# MIMXRT1061 register map
Vendor: nxp.com; File version: 1.0
CPU: CM7 r0p1, little endian, MPU, FPU, VTOR, 4 interrupt priority bits
Registers are 32-bit, read-write, reset 0x0 unless marked. A register's access mark holds for its fields unless they carry their own. Offsets are from the block's base; [hi:lo] are bit positions; {n}, {i} and the like mark numbered series; 'fields as' and 'values as' point back to an identical list.

## IOMUXC (part 4 of 4)
Base 0x401F8000; register names take the prefix IOMUXC_
0x4F4 LPSPI1_SDI_SELECT_INPUT — LPSPI1_SDI_SELECT_INPUT DAISY Register
  [0] DAISY — Selecting Pads Involved in Daisy Chain.
    0=GPIO_EMC_29_ALT3 (Selecting Pad: GPIO_EMC_29 for Mode: ALT3); 1=GPIO_SD_B0_03_ALT4 (Selecting Pad: GPIO_AD_B0_03 for Mode: ALT4)
0x4F8 LPSPI1_SDO_SELECT_INPUT — LPSPI1_SDO_SELECT_INPUT DAISY Register
  [0] DAISY — Selecting Pads Involved in Daisy Chain.
    0=GPIO_EMC_28_ALT3 (Selecting Pad: GPIO_EMC_28 for Mode: ALT3); 1=GPIO_SD_B0_02_ALT4 (Selecting Pad: GPIO_SD_B0_02 for Mode: ALT4)
0x4FC LPSPI2_PCS0_SELECT_INPUT — LPSPI2_PCS0_SELECT_INPUT DAISY Register
  [0] DAISY — Selecting Pads Involved in Daisy Chain.
    0=GPIO_SD_B1_06_ALT4 (Selecting Pad: GPIO_SD_B1_06 for Mode: ALT4); 1=GPIO_EMC_01_ALT2 (Selecting Pad: GPIO_EMC_01 for Mode: ALT2)
0x500 LPSPI2_SCK_SELECT_INPUT — LPSPI2_SCK_SELECT_INPUT DAISY Register
  [0] DAISY — Selecting Pads Involved in Daisy Chain.
    0=GPIO_SD_B1_07_ALT4 (Selecting Pad: GPIO_SD_B1_07 for Mode: ALT4); 1=GPIO_EMC_00_ALT2 (Selecting Pad: GPIO_EMC_00 for Mode: ALT2)
0x504 LPSPI2_SDI_SELECT_INPUT — LPSPI2_SDI_SELECT_INPUT DAISY Register
  [0] DAISY — Selecting Pads Involved in Daisy Chain.
    0=GPIO_SD_B1_09_ALT4 (Selecting Pad: GPIO_SD_B1_09 for Mode: ALT4); 1=GPIO_EMC_03_ALT2 (Selecting Pad: GPIO_EMC_03 for Mode: ALT2)
0x508 LPSPI2_SDO_SELECT_INPUT — LPSPI2_SDO_SELECT_INPUT DAISY Register
  [0] DAISY — Selecting Pads Involved in Daisy Chain.
    0=GPIO_SD_B1_08_ALT4 (Selecting Pad: GPIO_SD_B1_08 for Mode: ALT4); 1=GPIO_EMC_02_ALT2 (Selecting Pad: GPIO_EMC_02 for Mode: ALT2)
0x50C LPSPI3_PCS0_SELECT_INPUT — LPSPI3_PCS0_SELECT_INPUT DAISY Register
  [0] DAISY — Selecting Pads Involved in Daisy Chain.
    0=GPIO_AD_B0_03_ALT7 (Selecting Pad: GPIO_AD_B0_03 for Mode: ALT7); 1=GPIO_AD_B1_12_ALT2 (Selecting Pad: GPIO_AD_B1_12 for Mode: ALT2)
0x510 LPSPI3_SCK_SELECT_INPUT — LPSPI3_SCK_SELECT_INPUT DAISY Register
  [0] DAISY — Selecting Pads Involved in Daisy Chain.
    0=GPIO_AD_B0_00_ALT7 (Selecting Pad: GPIO_AD_B0_00 for Mode: ALT7); 1=GPIO_AD_B1_15_ALT2 (Selecting Pad: GPIO_AD_B1_15 for Mode: ALT2)
0x514 LPSPI3_SDI_SELECT_INPUT — LPSPI3_SDI_SELECT_INPUT DAISY Register
  [0] DAISY — Selecting Pads Involved in Daisy Chain.
    0=GPIO_AD_B0_02_ALT7 (Selecting Pad: GPIO_AD_B0_02 for Mode: ALT7); 1=GPIO_AD_B1_13_ALT2 (Selecting Pad: GPIO_AD_B1_13 for Mode: ALT2)
0x518 LPSPI3_SDO_SELECT_INPUT — LPSPI3_SDO_SELECT_INPUT DAISY Register
  [0] DAISY — Selecting Pads Involved in Daisy Chain.
    0=GPIO_AD_B0_01_ALT7 (Selecting Pad: GPIO_AD_B0_01 for Mode: ALT7); 1=GPIO_AD_B1_14_ALT2 (Selecting Pad: GPIO_AD_B1_14 for Mode: ALT2)
0x51C LPSPI4_PCS0_SELECT_INPUT — LPSPI4_PCS0_SELECT_INPUT DAISY Register
  [0] DAISY — Selecting Pads Involved in Daisy Chain.
    0=GPIO_B0_00_ALT3 (Selecting Pad: GPIO_B0_00 for Mode: ALT3); 1=GPIO_B1_04_ALT1 (Selecting Pad:GPIO_B1_04 for Mode: ALT1)
0x520 LPSPI4_SCK_SELECT_INPUT — LPSPI4_SCK_SELECT_INPUT DAISY Register
  [0] DAISY — Selecting Pads Involved in Daisy Chain.
    0=GPIO_B0_03_ALT3 (Selecting Pad: GPIO_B0_03 for Mode: ALT3); 1=GPIO_B1_07_ALT1 (Selecting Pad: GPIO_B1_07 for Mode: ALT1)
0x524 LPSPI4_SDI_SELECT_INPUT — LPSPI4_SDI_SELECT_INPUT DAISY Register
  [0] DAISY — Selecting Pads Involved in Daisy Chain.
    0=GPIO_B0_01_ALT3 (Selecting Pad: GPIO_B0_01 for Mode: ALT3); 1=GPIO_B1_05_ALT1 (Selecting Pad: GPIO_B1_05 for Mode: ALT1)
0x528 LPSPI4_SDO_SELECT_INPUT — LPSPI4_SDO_SELECT_INPUT DAISY Register
  [0] DAISY — Selecting Pads Involved in Daisy Chain.
    0=GPIO_B0_02_ALT3 (Selecting Pad: GPIO_B0_02 for Mode: ALT3); 1=GPIO_B1_06_ALT1 (Selecting Pad: GPIO_B1_06 for Mode: ALT1)
0x52C LPUART2_RX_SELECT_INPUT — LPUART2_RX_SELECT_INPUT DAISY Register
  [0] DAISY — Selecting Pads Involved in Daisy Chain.
    0=GPIO_SD_B1_10_ALT2 (Selecting Pad: GPIO_SD_B1_10 for Mode: ALT2); 1=GPIO_AD_B1_03_ALT2 (Selecting Pad: GPIO_AD_B1_03 for Mode: ALT2)
0x530 LPUART2_TX_SELECT_INPUT — LPUART2_TX_SELECT_INPUT DAISY Register
  [0] DAISY — Selecting Pads Involved in Daisy Chain.
    0=GPIO_SD_B1_11_ALT2 (Selecting Pad: GPIO_SD_B1_11 for Mode: ALT2); 1=GPIO_AD_B1_02_ALT2 (Selecting Pad: GPIO_AD_B1_02 for Mode: ALT2)
0x534 LPUART3_CTS_B_SELECT_INPUT — LPUART3_CTS_B_SELECT_INPUT DAISY Register
  [0] DAISY — Selecting Pads Involved in Daisy Chain.
    0=GPIO_EMC_15_ALT2 (Selecting Pad: GPIO_EMC_15 for Mode: ALT2); 1=GPIO_AD_B1_04_ALT2 (Selecting Pad: GPIO_AD_B1_04 for Mode: ALT2)
0x538 LPUART3_RX_SELECT_INPUT — LPUART3_RX_SELECT_INPUT DAISY Register
  [1:0] DAISY — Selecting Pads Involved in Daisy Chain.
    0=GPIO_AD_B1_07_ALT2 (Selecting Pad: GPIO_AD_B1_07 for Mode: ALT2); 1=GPIO_EMC_14_ALT2 (Selecting Pad: GPIO_EMC_14 for Mode: ALT2); 2=GPIO_B0_09_ALT3 (Selecting Pad: GPIO_B0_09 for Mode: ALT3)
0x53C LPUART3_TX_SELECT_INPUT — LPUART3_TX_SELECT_INPUT DAISY Register
  [1:0] DAISY — Selecting Pads Involved in Daisy Chain.
    0=GPIO_AD_B1_06_ALT2 (Selecting Pad: GPIO_AD_B1_06 for Mode: ALT2); 1=GPIO_EMC_13_ALT2 (Selecting Pad: GPIO_EMC_13 for Mode: ALT2); 2=GPIO_B0_08_ALT3 (Selecting Pad: GPIO_B0_08 for Mode: ALT3)
0x540 LPUART4_RX_SELECT_INPUT — LPUART4_RX_SELECT_INPUT DAISY Register
  [1:0] DAISY — Selecting Pads Involved in Daisy Chain.
    0=GPIO_SD_B1_01_ALT4 (Selecting Pad: GPIO_SD_B1_01 for Mode: ALT4); 1=GPIO_EMC_20_ALT2 (Selecting Pad: GPIO_EMC_20 for Mode: ALT2); 2=GPIO_B1_01_ALT2 (Selecting Pad: GPIO_B1_01 for Mode: ALT2)
0x544 LPUART4_TX_SELECT_INPUT — LPUART4_TX_SELECT_INPUT DAISY Register
  [1:0] DAISY — Selecting Pads Involved in Daisy Chain.
    0=GPIO_SD_B1_00_ALT4 (Selecting Pad: GPIO_SD_B1_00 for Mode: ALT4); 1=GPIO_EMC_19_ALT2 (Selecting Pad: GPIO_EMC_19 for Mode: ALT2); 2=GPIO_B1_00_ALT2 (Selecting Pad: GPIO_B1_00 for Mode: ALT2)
0x548 LPUART5_RX_SELECT_INPUT — LPUART5_RX_SELECT_INPUT DAISY Register
  [0] DAISY — Selecting Pads Involved in Daisy Chain.
    0=GPIO_EMC_24_ALT2 (Selecting Pad: GPIO_EMC_24 for Mode: ALT2); 1=GPIO_B1_13_ALT1 (Selecting Pad: GPIO_B1_13 for Mode: ALT1)
0x54C LPUART5_TX_SELECT_INPUT — LPUART5_TX_SELECT_INPUT DAISY Register
  [0] DAISY — Selecting Pads Involved in Daisy Chain.
    0=GPIO_EMC_23_ALT2 (Selecting Pad: GPIO_EMC_23 for Mode: ALT2); 1=GPIO_B1_12_ALT1 (Selecting Pad: GPIO_B1_12 for Mode: ALT1)
0x550 LPUART6_RX_SELECT_INPUT — LPUART6_RX_SELECT_INPUT DAISY Register
  [0] DAISY — Selecting Pads Involved in Daisy Chain.
    0=GPIO_EMC_26_ALT2 (Selecting Pad: GPIO_EMC_26 for Mode: ALT2); 1=GPIO_AD_B0_03_ALT2 (Selecting Pad: GPIO_AD_B0_03 for Mode: ALT2)
0x554 LPUART6_TX_SELECT_INPUT — LPUART6_TX_SELECT_INPUT DAISY Register
  [0] DAISY — Selecting Pads Involved in Daisy Chain.
    0=GPIO_EMC_25_ALT2 (Selecting Pad: GPIO_EMC_25 for Mode: ALT2); 1=GPIO_AD_B0_02_ALT2 (Selecting Pad: GPIO_AD_B0_02 for Mode: ALT2)
0x558 LPUART7_RX_SELECT_INPUT — LPUART7_RX_SELECT_INPUT DAISY Register
  [0] DAISY — Selecting Pads Involved in Daisy Chain.
    0=GPIO_SD_B1_09_ALT2 (Selecting Pad: GPIO_SD_B1_09 for Mode: ALT2); 1=GPIO_EMC_32_ALT2 (Selecting Pad: GPIO_EMC_32 for Mode: ALT2)
0x55C LPUART7_TX_SELECT_INPUT — LPUART7_TX_SELECT_INPUT DAISY Register
  [0] DAISY — Selecting Pads Involved in Daisy Chain.
    0=GPIO_SD_B1_08_ALT2 (Selecting Pad: GPIO_SD_B1_08 for Mode: ALT2); 1=GPIO_EMC_31_ALT2 (Selecting Pad:GPIO_EMC_31 for Mode: ALT2)
0x560 LPUART8_RX_SELECT_INPUT — LPUART8_RX_SELECT_INPUT DAISY Register
  [1:0] DAISY — Selecting Pads Involved in Daisy Chain.
    0=GPIO_SD_B0_05_ALT2 (Selecting Pad: GPIO_SD_B0_05 for Mode: ALT2); 1=GPIO_AD_B1_11_ALT2 (Selecting Pad: GPIO_AD_B1_11 for Mode: ALT2); 2=GPIO_EMC_39_ALT2 (Selecting Pad: GPIO_EMC_39 for Mode: ALT2)
0x564 LPUART8_TX_SELECT_INPUT — LPUART8_TX_SELECT_INPUT DAISY Register
  [1:0] DAISY — Selecting Pads Involved in Daisy Chain.
    0=GPIO_SD_B0_04_ALT2 (Selecting Pad: GPIO_SD_B0_04 for Mode: ALT2); 1=GPIO_AD_B1_10_ALT2 (Selecting Pad: GPIO_AD_B1_10 for Mode: ALT2); 2=GPIO_EMC_38_ALT2 (Selecting Pad: GPIO_EMC_38 for Mode: ALT2)
0x568 NMI_SELECT_INPUT — NMI_GLUE_NMI_SELECT_INPUT DAISY Register
  [0] DAISY — Selecting Pads Involved in Daisy Chain.
    0=GPIO_AD_B0_12_ALT7 (Selecting Pad: GPIO_AD_B0_12 for Mode: ALT7); 1=WAKEUP_ALT7 (Selecting Pad: WAKEUP for Mode: ALT7)
{0x56C+4i} QTIMER2_TIMER{i}_SELECT_INPUT (i=0..2) — QTIMER2_TIMER{i}_SELECT_INPUT DAISY Register
  [0] DAISY — Selecting Pads Involved in Daisy Chain.
    0=GPIO_EMC_{i+19}_ALT4 (Selecting Pad: GPIO_EMC_{i+19} for Mode: ALT4); 1=GPIO_B0_{i+3:02}_ALT1 (Selecting Pad: GPIO_B0_{i+3:02} for Mode: ALT1)
0x578 QTIMER2_TIMER3_SELECT_INPUT — QTIMER2_TIMER3_SELECT_INPUT DAISY Register
  [0] DAISY — Selecting Pads Involved in Daisy Chain.
    0=GPIO_EMC_22_ALT4 (Selecting Pad: GPIO_EMC_22 for Mode: ALT4); 1=GPIO_B1_09_ALT1 (Selecting Pad: GPIO_B1_09 for Mode: ALT1)
0x57C QTIMER3_TIMER0_SELECT_INPUT — QTIMER3_TIMER0_SELECT_INPUT DAISY Register
  [1:0] DAISY — Selecting Pads Involved in Daisy Chain.
    0=GPIO_EMC_15_ALT4 (Selecting Pad: GPIO_EMC_15 for Mode: ALT4); 1=GPIO_AD_B1_00_ALT1 (Selecting Pad: GPIO_AD_B1_00 for Mode: ALT1); 2=GPIO_B0_06_ALT1 (Selecting Pad: GPIO_B0_06 for Mode: ALT1)
0x580 QTIMER3_TIMER1_SELECT_INPUT — QTIMER3_TIMER1_SELECT_INPUT DAISY Register
  [1:0] DAISY — Selecting Pads Involved in Daisy Chain.
    0=GPIO_AD_B1_01_ALT1 (Selecting Pad: GPIO_AD_B1_01 for Mode: ALT1); 1=GPIO_EMC_16_ALT4 (Selecting Pad: GPIO_EMC_16 for Mode: ALT4); 2=GPIO_B0_07_ALT1 (Selecting Pad: GPIO_B0_07 for Mode: ALT1)
0x584 QTIMER3_TIMER2_SELECT_INPUT — QTIMER3_TIMER2_SELECT_INPUT DAISY Register
  [1:0] DAISY — Selecting Pads Involved in Daisy Chain.
    0=GPIO_EMC_17_ALT4 (Selecting Pad: GPIO_EMC_17 for Mode: ALT4); 1=GPIO_AD_B1_02_ALT1 (Selecting Pad: GPIO_AD_B1_02 for Mode: ALT1); 2=GPIO_B0_08_ALT1 (Selecting Pad: GPIO_B0_08 for Mode: ALT1)
0x588 QTIMER3_TIMER3_SELECT_INPUT — QTIMER3_TIMER3_SELECT_INPUT DAISY Register
  [1:0] DAISY — Selecting Pads Involved in Daisy Chain.
    0=GPIO_EMC_18_ALT4 (Selecting Pad: GPIO_EMC_18 for Mode: ALT4); 1=GPIO_AD_B1_03_ALT1 (Selecting Pad: GPIO_AD_B1_03 for Mode: ALT1); 2=GPIO_B1_10_ALT1 (Selecting Pad: GPIO_B1_10 for Mode: ALT1)
0x58C SAI1_MCLK2_SELECT_INPUT — SAI1_MCLK2_SELECT_INPUT DAISY Register
  [1:0] DAISY — Selecting Pads Involved in Daisy Chain.
    0=GPIO_SD_B1_03_ALT3 (Selecting Pad: GPIO_SD_B1_03 for Mode: ALT3); 1=GPIO_AD_B1_09_ALT3 (Selecting Pad: GPIO_AD_B1_09 for Mode: ALT3); 2=GPIO_B0_13_ALT3 (Selecting Pad: GPIO_B0_13 for Mode: ALT3)
0x590 SAI1_RX_BCLK_SELECT_INPUT — SAI1_RX_BCLK_SELECT_INPUT DAISY Register
  [1:0] DAISY — Selecting Pads Involved in Daisy Chain.
    0=GPIO_SD_B1_05_ALT3 (Selecting Pad: GPIO_SD_B1_05 for Mode: ALT3); 1=GPIO_AD_B1_11_ALT3 (Selecting Pad: GPIO_AD_B1_11 for Mode: ALT3); 2=GPIO_B0_15_ALT3 (Selecting Pad: GPIO_B0_15 for Mode: ALT3)
0x594 SAI1_RX_DATA0_SELECT_INPUT — SAI1_RX_DATA0_SELECT_INPUT DAISY Register
  [1:0] DAISY — Selecting Pads Involved in Daisy Chain.
    0=GPIO_SD_B1_06_ALT3 (Selecting Pad: GPIO_SD_B1_06 for Mode: ALT3); 1=GPIO_AD_B1_12_ALT3 (Selecting Pad: GPIO_AD_B1_12 for Mode: ALT3); 2=GPIO_B1_00_ALT3 (Selecting Pad: GPIO_B1_00 for Mode: ALT3)
{0x594+4i} SAI1_RX_DATA{i}_SELECT_INPUT (i=1..3) — SAI1_RX_DATA{i}_SELECT_INPUT DAISY Register
  [0] DAISY — Selecting Pads Involved in Daisy Chain.
    0=GPIO_SD_B1_{i-1:02}_ALT3 (Selecting Pad: GPIO_SD_B1_{i-1:02} for Mode: ALT3); 1=GPIO_B0_{i+9}_ALT3 (Selecting Pad: GPIO_B0_{i+9} for Mode: ALT3)
0x5A4 SAI1_RX_SYNC_SELECT_INPUT — SAI1_RX_SYNC_SELECT_INPUT DAISY Register
  [1:0] DAISY — Selecting Pads Involved in Daisy Chain.
    0=GPIO_SD_B1_04_ALT3 (Selecting Pad: GPIO_SD_B1_04 for Mode: ALT3); 1=GPIO_AD_B1_10_ALT3 (Selecting Pad: GPIO_AD_B1_10 for Mode: ALT3); 2=GPIO_B0_14_ALT3 (Selecting Pad: GPIO_B0_14 for Mode: ALT3)
0x5A8 SAI1_TX_BCLK_SELECT_INPUT — SAI1_TX_BCLK_SELECT_INPUT DAISY Register
  [1:0] DAISY — Selecting Pads Involved in Daisy Chain.
    0=GPIO_SD_B1_08_ALT3 (Selecting Pad: GPIO_SD_B1_08 for Mode: ALT3); 1=GPIO_AD_B1_14_ALT3 (Selecting Pad: GPIO_AD_B1_14 for Mode: ALT3); 2=GPIO_B1_02_ALT3 (Selecting Pad: GPIO_B1_02 for Mode: ALT3)
0x5AC SAI1_TX_SYNC_SELECT_INPUT — SAI1_TX_SYNC_SELECT_INPUT DAISY Register
  [1:0] DAISY — Selecting Pads Involved in Daisy Chain.
    0=GPIO_SD_B1_09_ALT3 (Selecting Pad: GPIO_SD_B1_09 for Mode: ALT3); 1=GPIO_AD_B1_15_ALT3 (Selecting Pad: GPIO_AD_B1_15 for Mode: ALT3); 2=GPIO_B1_03_ALT3 (Selecting Pad: GPIO_B1_03 for Mode: ALT3)
0x5B0 SAI2_MCLK2_SELECT_INPUT — SAI2_MCLK2_SELECT_INPUT DAISY Register
  [0] DAISY — Selecting Pads Involved in Daisy Chain.
    0=GPIO_EMC_07_ALT2 (Selecting Pad: GPIO_EMC_07 for Mode: ALT2); 1=GPIO_AD_B0_10_ALT3 (Selecting Pad: GPIO_AD_B0_10 for Mode: ALT3)
0x5B4 SAI2_RX_BCLK_SELECT_INPUT — SAI2_RX_BCLK_SELECT_INPUT DAISY Register
  [0] DAISY — Selecting Pads Involved in Daisy Chain.
    0=GPIO_EMC_10_ALT2 (Selecting Pad: GPIO_EMC_10 for Mode: ALT2); 1=GPIO_AD_B0_06_ALT3 (Selecting Pad: GPIO_AD_B0_06 for Mode: ALT3)
0x5B8 SAI2_RX_DATA0_SELECT_INPUT — SAI2_RX_DATA0_SELECT_INPUT DAISY Register
  [0] DAISY — Selecting Pads Involved in Daisy Chain.
    0=GPIO_EMC_08_ALT2 (Selecting Pad: GPIO_EMC_08 for Mode: ALT2); 1=GPIO_AD_B0_08_ALT3 (Selecting Pad: GPIO_AD_B0_08 for Mode: ALT3)
0x5BC SAI2_RX_SYNC_SELECT_INPUT — SAI2_RX_SYNC_SELECT_INPUT DAISY Register
  [0] DAISY — Selecting Pads Involved in Daisy Chain.
    0=GPIO_EMC_09_ALT2 (Selecting Pad: GPIO_EMC_09 for Mode: ALT2); 1=GPIO_AD_B0_07_ALT3 (Selecting Pad: GPIO_AD_B0_07 for Mode: ALT3)
0x5C0 SAI2_TX_BCLK_SELECT_INPUT — SAI2_TX_BCLK_SELECT_INPUT DAISY Register
  [0] DAISY — Selecting Pads Involved in Daisy Chain.
    0=GPIO_EMC_06_ALT2 (Selecting Pad: GPIO_EMC_06 for Mode: ALT2); 1=GPIO_AD_B0_05_ALT3 (Selecting Pad: GPIO_AD_B0_05 for Mode: ALT3)
0x5C4 SAI2_TX_SYNC_SELECT_INPUT — SAI2_TX_SYNC_SELECT_INPUT DAISY Register
  [0] DAISY — Selecting Pads Involved in Daisy Chain.
    0=GPIO_EMC_05_ALT2 (Selecting Pad: GPIO_EMC_05 for Mode: ALT2); 1=GPIO_AD_B0_04_ALT3 (Selecting Pad: GPIO_AD_B0_04 for Mode: ALT3)
0x5C8 SPDIF_IN_SELECT_INPUT — SPDIF_IN_SELECT_INPUT DAISY Register
  [0] DAISY — Selecting Pads Involved in Daisy Chain.
    0=GPIO_AD_B1_03_ALT3 (Selecting Pad: GPIO_AD_B1_03 for Mode: ALT3); 1=GPIO_EMC_16_ALT3 (Selecting Pad: GPIO_EMC_16 for Mode: ALT3)
0x5CC USB_OTG2_OC_SELECT_INPUT — USB_OTG2_OC_SELECT_INPUT DAISY Register
  [0] DAISY — Selecting Pads Involved in Daisy Chain.
    0=GPIO_AD_B0_14_ALT0 (Selecting Pad: GPIO_AD_B0_14 for Mode: ALT0); 1=GPIO_EMC_40_ALT3 (Selecting Pad: GPIO_EMC_40 for Mode: ALT3)
0x5D0 USB_OTG1_OC_SELECT_INPUT — USB_OTG1_OC_SELECT_INPUT DAISY Register
  [0] DAISY — Selecting Pads Involved in Daisy Chain.
    0=GPIO_AD_B0_03_ALT3 (Selecting Pad: GPIO_AD_B0_03 for Mode: ALT3); 1=GPIO_AD_B1_03_ALT0 (Selecting Pad: GPIO_AD_B1_03 for Mode: ALT0)
0x5D4 USDHC1_CD_B_SELECT_INPUT — USDHC1_CD_B_SELECT_INPUT DAISY Register
  [1:0] DAISY — Selecting Pads Involved in Daisy Chain.
    0=GPIO_EMC_35_ALT6 (Selecting Pad: GPIO_EMC_35 for Mode: ALT6); 1=GPIO_AD_B1_02_ALT6 (Selecting Pad: GPIO_AD_B1_02 for Mode: ALT6); 2=GPIO_B1_12_ALT6 (Selecting Pad: GPIO_B1_12 for Mode: ALT6)
0x5D8 USDHC1_WP_SELECT_INPUT — USDHC1_WP_SELECT_INPUT DAISY Register
  [1:0] DAISY — Selecting Pads Involved in Daisy Chain.
    0=GPIO_EMC_12_ALT3 (Selecting Pad: GPIO_EMC_12 for Mode: ALT3); 1=GPIO_EMC_36_ALT6 (Selecting Pad: GPIO_EMC_36for Mode: ALT6); 2=GPIO_AD_B1_00_ALT6 (Selecting Pad:GPIO_AD_B1_00 for Mode: ALT6); 3=GPIO_B1_13_ALT6 (Selecting Pad: GPIO_B1_13 for Mode: ALT6)
0x5DC USDHC2_CLK_SELECT_INPUT — USDHC2_CLK_SELECT_INPUT DAISY Register
  [0] DAISY — Selecting Pads Involved in Daisy Chain.
    0=GPIO_SD_B1_04_ALT0 (Selecting Pad: GPIO_SD_B1_04 for Mode: ALT0); 1=GPIO_AD_B1_09_ALT6 (Selecting Pad: GPIO_AD_B1_09 for Mode: ALT6)
0x5E0 USDHC2_CD_B_SELECT_INPUT — USDHC2_CD_B_SELECT_INPUT DAISY Register
  [0] DAISY — Selecting Pads Involved in Daisy Chain.
    0=GPIO_AD_B1_03_ALT6 (Selecting Pad:GPIO_AD_B1_03 for Mode: ALT6); 1=GPIO_EMC_39_ALT6 (Selecting Pad: GPIO_EMC_39 for Mode: ALT6)
0x5E4 USDHC2_CMD_SELECT_INPUT — USDHC2_CMD_SELECT_INPUT DAISY Register
  [0] DAISY — Selecting Pads Involved in Daisy Chain.
    0=GPIO_SD_B1_05_ALT0 (Selecting Pad: GPIO_SD_B1_05 for Mode: ALT0); 1=GPIO_AD_B1_08_ALT6 (Selecting Pad: GPIO_AD_B1_08 for Mode: ALT6)
0x5E8 USDHC2_DATA0_SELECT_INPUT — USDHC2_DATA0_SELECT_INPUT DAISY Register
  [0] DAISY — Selecting Pads Involved in Daisy Chain.
    0=GPIO_SD_B1_03_ALT0 (Selecting Pad: GPIO_SD_B1_03 for Mode: ALT0); 1=GPIO_AD_B1_04_ALT6 (Selecting Pad:GPIO_AD_B1_04 for Mode: ALT6)
0x5EC USDHC2_DATA1_SELECT_INPUT — USDHC2_DATA1_SELECT_INPUT DAISY Register
  [0] DAISY — Selecting Pads Involved in Daisy Chain.
    0=GPIO_SD_B1_02_ALT0 (Selecting Pad: GPIO_SD_B1_02 for Mode: ALT0); 1=GPIO_AD_B1_05_ALT6 (Selecting Pad: GPIO_AD_B1_05 for Mode: ALT6)
0x5F0 USDHC2_DATA2_SELECT_INPUT — USDHC2_DATA2_SELECT_INPUT DAISY Register
  [0] DAISY — Selecting Pads Involved in Daisy Chain.
    0=GPIO_SD_B1_01_ALT0 (Selecting Pad: GPIO_SD_B1_01 for Mode: ALT0); 1=GPIO_AD_B1_06_ALT6 (Selecting Pad: GPIO_AD_B1_06 for Mode: ALT6)
0x5F4 USDHC2_DATA3_SELECT_INPUT — USDHC2_DATA3_SELECT_INPUT DAISY Register
  [0] DAISY — Selecting Pads Involved in Daisy Chain.
    0=GPIO_SD_B1_00_ALT0 (Selecting Pad: GPIO_SD_B1_00 for Mode: ALT0); 1=GPIO_AD_B1_07_ALT6 (Selecting Pad: GPIO_AD_B1_07 for Mode: ALT6)
{0x5E8+4i} USDHC2_DATA{i}_SELECT_INPUT (i=4..7) — USDHC2_DATA{i}_SELECT_INPUT DAISY Register
  [0] DAISY — Selecting Pads Involved in Daisy Chain.
    0=GPIO_SD_B1_{i+4:02}_ALT0 (Selecting Pad: GPIO_SD_B1_{i+4:02} for Mode: ALT0); 1=GPIO_AD_B1_{i+8}_ALT6 (Selecting Pad: GPIO_AD_B1_{i+8} for Mode: ALT6)
0x608 USDHC2_WP_SELECT_INPUT — USDHC2_WP_SELECT_INPUT DAISY Register
  [0] DAISY — Selecting Pads Involved in Daisy Chain.
    0=GPIO_EMC_37_ALT6 (Selecting Pad: GPIO_EMC_37 for Mode: ALT6); 1=GPIO_AD_B1_10_ALT6 (Selecting Pad: GPIO_AD_B1_10 for Mode: ALT6)
0x60C XBAR1_IN02_SELECT_INPUT — XBAR1_IN02_SELECT_INPUT DAISY Register
  [0] DAISY — Selecting Pads Involved in Daisy Chain.
    0=GPIO_EMC_00_ALT3 (Selecting Pad: GPIO_EMC_00 for Mode: ALT3); 1=GPIO_B1_14_ALT3 (Selecting Pad: GPIO_B1_14 for Mode: ALT3)
0x610 XBAR1_IN03_SELECT_INPUT — XBAR1_IN03_SELECT_INPUT DAISY Register
  [0] DAISY — Selecting Pads Involved in Daisy Chain.
    0=GPIO_EMC_01_ALT3 (Selecting Pad: GPIO_EMC_01 for Mode: ALT3); 1=GPIO_B1_15_ALT3 (Selecting Pad: GPIO_B1_15 for Mode: ALT3)
{0x604+4i} XBAR1_IN{i:02}_SELECT_INPUT (i=4..9) — XBAR1_IN{i:02}_SELECT_INPUT DAISY Register
  [0] DAISY — Selecting Pads Involved in Daisy Chain.
    0=GPIO_EMC_{i-2:02}_ALT3 (Selecting Pad: GPIO_EMC_{i-2:02} for Mode: ALT3); 1=GPIO_SD_B0_{i-4:02}_ALT3 (Selecting Pad: GPIO_SD_B0_{i-4:02} for Mode: ALT3)
0x62C XBAR1_IN17_SELECT_INPUT — XBAR1_IN17_SELECT_INPUT DAISY Register
  [1:0] DAISY — Selecting Pads Involved in Daisy Chain.
    0=GPIO_EMC_08_ALT3 (Selecting Pad: GPIO_EMC_08 for Mode: ALT3); 1=GPIO_AD_B0_03_ALT1 (Selecting Pad: GPIO_AD_B0_03 for Mode: ALT1); 2=GPIO_AD_B0_05_ALT6 (Selecting Pad: GPIO_AD_B0_05 for Mode: ALT6); 3=GPIO_B1_03_ALT1 (Selecting Pad: GPIO_B1_03 for Mode: ALT1)
0x630 XBAR1_IN18_SELECT_INPUT — XBAR1_IN18_SELECT_INPUT DAISY Register
  [0] DAISY — Selecting Pads Involved in Daisy Chain.
    0=GPIO_EMC_35_ALT1 (Selecting Pad: GPIO_EMC_35 for Mode: ALT1); 1=GPIO_AD_B0_06_ALT6 (Selecting Pad: GPIO_AD_B0_06 for Mode: ALT6)
0x634 XBAR1_IN20_SELECT_INPUT — XBAR1_IN20_SELECT_INPUT DAISY Register
  [0] DAISY — Selecting Pads Involved in Daisy Chain.
    0=GPIO_EMC_15_ALT1 (Selecting Pad: GPIO_EMC_15 for Mode: ALT1); 1=GPIO_AD_B0_08_ALT6 (Selecting Pad: GPIO_AD_B0_08 for Mode: ALT6)
0x638 XBAR1_IN22_SELECT_INPUT — XBAR1_IN22_SELECT_INPUT DAISY Register
  [0] DAISY — Selecting Pads Involved in Daisy Chain.
    0=GPIO_EMC_36_ALT1 (Selecting Pad: GPIO_EMC_36 for Mode: ALT1); 1=GPIO_AD_B0_10_ALT6 (Selecting Pad: GPIO_AD_B0_10 for Mode: ALT6)
0x63C XBAR1_IN23_SELECT_INPUT — XBAR1_IN23_SELECT_INPUT DAISY Register
  [0] DAISY — Selecting Pads Involved in Daisy Chain.
    0=GPIO_EMC_37_ALT1 (Selecting Pad: GPIO_EMC_37 for Mode: ALT1); 1=GPIO_AD_B0_11_ALT6 (Selecting Pad: GPIO_AD_B0_11 for Mode: ALT6)
0x640 XBAR1_IN24_SELECT_INPUT — XBAR1_IN24_SELECT_INPUT DAISY Register
  [0] DAISY — Selecting Pads Involved in Daisy Chain.
    0=GPIO_EMC_12_ALT1 (Selecting Pad: GPIO_EMC_12 for Mode: ALT1); 1=GPIO_AD_B0_14_ALT1 (Selecting Pad: GPIO_AD_B0_14 for Mode: ALT1)
0x644 XBAR1_IN14_SELECT_INPUT — XBAR1_IN14_SELECT_INPUT DAISY Register
  [0] DAISY — Selecting Pads Involved in Daisy Chain.
    0=GPIO_AD_B0_00_ALT1 (Selecting Pad: GPIO_AD_B0_00 for Mode: ALT1); 1=GPIO_B1_00_ALT1 (Selecting Pad:GPIO_B1_00 for Mode: ALT1)
0x648 XBAR1_IN15_SELECT_INPUT — XBAR1_IN15_SELECT_INPUT DAISY Register
  [0] DAISY — Selecting Pads Involved in Daisy Chain.
    0=GPIO_AD_B0_01_ALT1 (Selecting Pad: GPIO_AD_B0_01 for Mode: ALT1); 1=GPIO_B1_01_ALT1 (Selecting Pad: GPIO_B1_01 for Mode: ALT1)
0x64C XBAR1_IN16_SELECT_INPUT — XBAR1_IN16_SELECT_INPUT DAISY Register
  [0] DAISY — Selecting Pads Involved in Daisy Chain.
    0=GPIO_AD_B0_02_ALT1 (Selecting Pad: GPIO_AD_B0_02 for Mode: ALT1); 1=GPIO_B1_02_ALT1 (Selecting Pad: GPIO_B1_02 for Mode: ALT1)
0x650 XBAR1_IN25_SELECT_INPUT — XBAR1_IN25_SELECT_INPUT DAISY Register
  [0] DAISY — Selecting Pads Involved in Daisy Chain.
    0=GPIO_AD_B0_15_ALT1 (Selecting Pad: GPIO_AD_B0_15 for Mode: ALT1); 1=GPIO_EMC_13_ALT1 (Selecting Pad: GPIO_EMC_13 for Mode: ALT1)
0x654 XBAR1_IN19_SELECT_INPUT — XBAR1_IN19_SELECT_INPUT DAISY Register
  [0] DAISY — Selecting Pads Involved in Daisy Chain.
    0=GPIO_EMC_14_ALT1 (Selecting Pad: GPIO_EMC_14 for Mode: ALT1); 1=GPIO_AD_B0_07_ALT6 (Selecting Pad: GPIO_AD_B0_07 for Mode: ALT6)
0x658 XBAR1_IN21_SELECT_INPUT — XBAR1_IN23_SELECT_INPUT DAISY Register
  [0] DAISY — Selecting Pads Involved in Daisy Chain.
    0=GPIO_EMC_16_ALT1 (Selecting Pad: GPIO_EMC_16 for Mode: ALT1); 1=GPIO_AD_B0_09_ALT6 (Selecting Pad: GPIO_AD_B0_09 for Mode: ALT6)
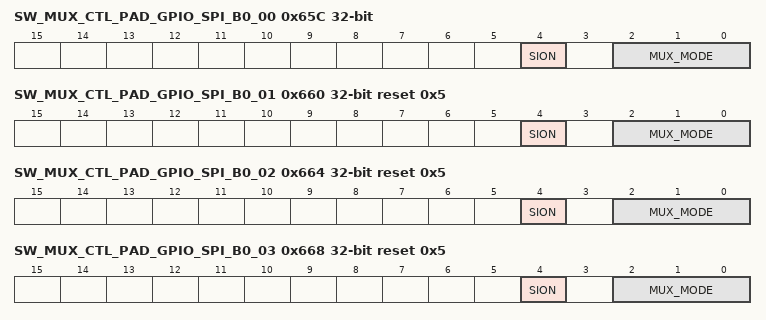
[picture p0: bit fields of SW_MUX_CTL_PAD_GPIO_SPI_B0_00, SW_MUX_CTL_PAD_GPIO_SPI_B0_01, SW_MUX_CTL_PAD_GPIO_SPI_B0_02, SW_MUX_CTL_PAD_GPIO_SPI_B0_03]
0x65C SW_MUX_CTL_PAD_GPIO_SPI_B0_00 — SW_MUX_CTL_PAD_GPIO_SPI_B0_00 SW MUX Control Register
  [4] SION — Software Input On Field.
    0=DISABLED (Input Path is determined by functionality); 1=ENABLED (Force input path of pad GPIO_SPI_B0_00)
  [2:0] MUX_MODE — MUX Mode Select Field.
    5=ALT5 (Select mux mode: ALT5 mux port: GPIO10_IO00 of instance: gpio10)
0x660 SW_MUX_CTL_PAD_GPIO_SPI_B0_01 reset 0x5 — SW_MUX_CTL_PAD_GPIO_SPI_B0_01 SW MUX Control Register
  [4] SION — Software Input On Field.
    0=DISABLED (Input Path is determined by functionality); 1=ENABLED (Force input path of pad GPIO_SPI_B0_01)
  [2:0] MUX_MODE — MUX Mode Select Field.
    0=ALT0 (Select mux mode: ALT0 mux port: FLEXSPI2_B_SCLK of instance: flexspi2); 5=ALT5 (Select mux mode: ALT5 mux port: GPIO10_IO01 of instance: gpio10)
0x664 SW_MUX_CTL_PAD_GPIO_SPI_B0_02 reset 0x5 — SW_MUX_CTL_PAD_GPIO_SPI_B0_02 SW MUX Control Register
  [4] SION — Software Input On Field.
    0=DISABLED (Input Path is determined by functionality); 1=ENABLED (Force input path of pad GPIO_SPI_B0_02)
  [2:0] MUX_MODE — MUX Mode Select Field.
    0=ALT0 (Select mux mode: ALT0 mux port: FLEXSPI2_A_DATA00 of instance: flexspi2); 5=ALT5 (Select mux mode: ALT5 mux port: GPIO10_IO02 of instance: gpio10)
0x668 SW_MUX_CTL_PAD_GPIO_SPI_B0_03 reset 0x5 — SW_MUX_CTL_PAD_GPIO_SPI_B0_03 SW MUX Control Register
  [4] SION — Software Input On Field.
    0=DISABLED (Input Path is determined by functionality); 1=ENABLED (Force input path of pad GPIO_SPI_B0_03)
  [2:0] MUX_MODE — MUX Mode Select Field.
    0=ALT0 (Select mux mode: ALT0 mux port: FLEXSPI2_B_DATA02 of instance: flexspi2); 5=ALT5 (Select mux mode: ALT5 mux port: GPIO10_IO03 of instance: gpio10)
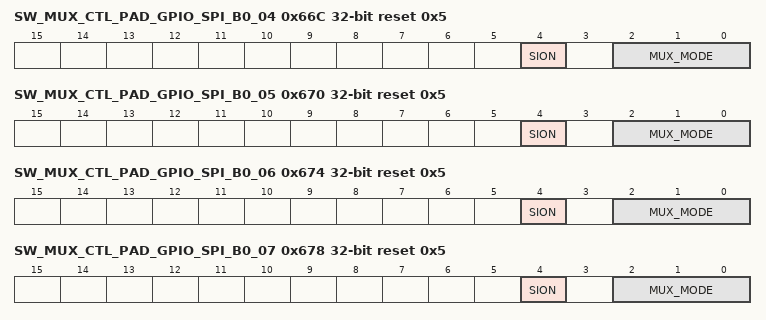
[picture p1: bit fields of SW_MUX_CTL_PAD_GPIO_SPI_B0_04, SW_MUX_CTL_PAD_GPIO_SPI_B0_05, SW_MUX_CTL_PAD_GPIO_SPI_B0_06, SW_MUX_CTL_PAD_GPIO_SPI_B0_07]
0x66C SW_MUX_CTL_PAD_GPIO_SPI_B0_04 reset 0x5 — SW_MUX_CTL_PAD_GPIO_SPI_B0_04 SW MUX Control Register
  [4] SION — Software Input On Field.
    0=DISABLED (Input Path is determined by functionality); 1=ENABLED (Force input path of pad GPIO_SPI_B0_04)
  [2:0] MUX_MODE — MUX Mode Select Field.
    0=ALT0 (Select mux mode: ALT0 mux port: FLEXSPI2_B_DATA03 of instance: flexspi2); 5=ALT5 (Select mux mode: ALT5 mux port: GPIO10_IO04 of instance: gpio10)
0x670 SW_MUX_CTL_PAD_GPIO_SPI_B0_05 reset 0x5 — SW_MUX_CTL_PAD_GPIO_SPI_B0_05 SW MUX Control Register
  [4] SION — Software Input On Field.
    0=DISABLED (Input Path is determined by functionality); 1=ENABLED (Force input path of pad GPIO_SPI_B0_05)
  [2:0] MUX_MODE — MUX Mode Select Field.
    0=ALT0 (Select mux mode: ALT0 mux port: FLEXSPI2_A_SS0_B of instance: flexspi2); 5=ALT5 (Select mux mode: ALT5 mux port: GPIO10_IO05 of instance: gpio10)
0x674 SW_MUX_CTL_PAD_GPIO_SPI_B0_06 reset 0x5 — SW_MUX_CTL_PAD_GPIO_SPI_B0_06 SW MUX Control Register
  [4] SION — Software Input On Field.
    0=DISABLED (Input Path is determined by functionality); 1=ENABLED (Force input path of pad GPIO_SPI_B0_06)
  [2:0] MUX_MODE — MUX Mode Select Field.
    0=ALT0 (Select mux mode: ALT0 mux port: FLEXSPI2_A_DATA02 of instance: flexspi2); 5=ALT5 (Select mux mode: ALT5 mux port: GPIO10_IO06 of instance: gpio10)
0x678 SW_MUX_CTL_PAD_GPIO_SPI_B0_07 reset 0x5 — SW_MUX_CTL_PAD_GPIO_SPI_B0_07 SW MUX Control Register
  [4] SION — Software Input On Field.
    0=DISABLED (Input Path is determined by functionality); 1=ENABLED (Force input path of pad GPIO_SPI_B0_07)
  [2:0] MUX_MODE — MUX Mode Select Field.
    0=ALT0 (Select mux mode: ALT0 mux port: FLEXSPI2_B_DATA01 of instance: flexspi2); 5=ALT5 (Select mux mode: ALT5 mux port: GPIO10_IO07 of instance: gpio10)
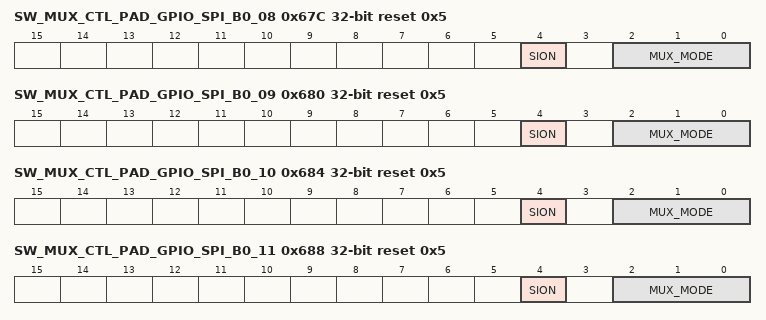
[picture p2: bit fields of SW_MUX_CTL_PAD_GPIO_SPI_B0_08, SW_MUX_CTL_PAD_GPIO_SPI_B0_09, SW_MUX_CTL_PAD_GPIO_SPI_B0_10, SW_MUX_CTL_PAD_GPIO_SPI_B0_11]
0x67C SW_MUX_CTL_PAD_GPIO_SPI_B0_08 reset 0x5 — SW_MUX_CTL_PAD_GPIO_SPI_B0_08 SW MUX Control Register
  [4] SION — Software Input On Field.
    0=DISABLED (Input Path is determined by functionality); 1=ENABLED (Force input path of pad GPIO_SPI_B0_08)
  [2:0] MUX_MODE — MUX Mode Select Field.
    0=ALT0 (Select mux mode: ALT0 mux port: FLEXSPI2_A_SCLK of instance: flexspi2); 5=ALT5 (Select mux mode: ALT5 mux port: GPIO10_IO08 of instance: gpio10)
0x680 SW_MUX_CTL_PAD_GPIO_SPI_B0_09 reset 0x5 — SW_MUX_CTL_PAD_GPIO_SPI_B0_09 SW MUX Control Register
  [4] SION — Software Input On Field.
    0=DISABLED (Input Path is determined by functionality); 1=ENABLED (Force input path of pad GPIO_SPI_B0_09)
  [2:0] MUX_MODE — MUX Mode Select Field.
    0=ALT0 (Select mux mode: ALT0 mux port: FLEXSPI2_A_DQS of instance: flexspi2); 5=ALT5 (Select mux mode: ALT5 mux port: GPIO10_IO09 of instance: gpio10)
0x684 SW_MUX_CTL_PAD_GPIO_SPI_B0_10 reset 0x5 — SW_MUX_CTL_PAD_GPIO_SPI_B0_10 SW MUX Control Register
  [4] SION — Software Input On Field.
    0=DISABLED (Input Path is determined by functionality); 1=ENABLED (Force input path of pad GPIO_SPI_B0_10)
  [2:0] MUX_MODE — MUX Mode Select Field.
    0=ALT0 (Select mux mode: ALT0 mux port: FLEXSPI2_A_DATA03 of instance: flexspi2); 5=ALT5 (Select mux mode: ALT5 mux port: GPIO10_IO10 of instance: gpio10)
0x688 SW_MUX_CTL_PAD_GPIO_SPI_B0_11 reset 0x5 — SW_MUX_CTL_PAD_GPIO_SPI_B0_11 SW MUX Control Register
  [4] SION — Software Input On Field.
    0=DISABLED (Input Path is determined by functionality); 1=ENABLED (Force input path of pad GPIO_SPI_B0_11)
  [2:0] MUX_MODE — MUX Mode Select Field.
    0=ALT0 (Select mux mode: ALT0 mux port: FLEXSPI2_B_DATA00 of instance: flexspi2); 5=ALT5 (Select mux mode: ALT5 mux port: GPIO10_IO11 of instance: gpio10)
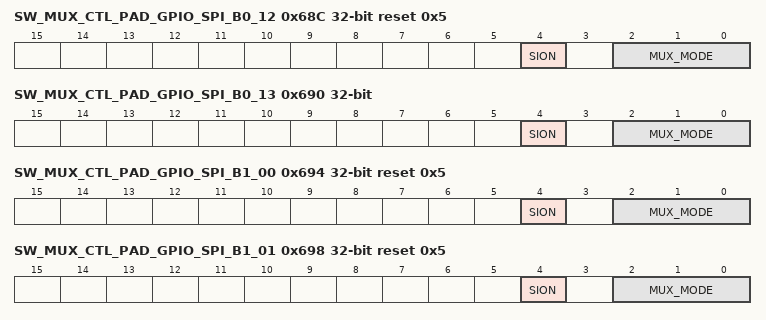
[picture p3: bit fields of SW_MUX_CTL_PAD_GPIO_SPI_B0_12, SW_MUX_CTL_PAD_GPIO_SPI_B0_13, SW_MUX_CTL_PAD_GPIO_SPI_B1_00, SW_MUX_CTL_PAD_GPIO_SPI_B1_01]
0x68C SW_MUX_CTL_PAD_GPIO_SPI_B0_12 reset 0x5 — SW_MUX_CTL_PAD_GPIO_SPI_B0_12 SW MUX Control Register
  [4] SION — Software Input On Field.
    0=DISABLED (Input Path is determined by functionality); 1=ENABLED (Force input path of pad GPIO_SPI_B0_12)
  [2:0] MUX_MODE — MUX Mode Select Field.
    0=ALT0 (Select mux mode: ALT0 mux port: FLEXSPI2_A_DATA01 of instance: flexspi2); 5=ALT5 (Select mux mode: ALT5 mux port: GPIO10_IO12 of instance: gpio10)
0x690 SW_MUX_CTL_PAD_GPIO_SPI_B0_13 — SW_MUX_CTL_PAD_GPIO_SPI_B0_13 SW MUX Control Register
  [4] SION — Software Input On Field.
    0=DISABLED (Input Path is determined by functionality); 1=ENABLED (Force input path of pad GPIO_SPI_B0_13)
  [2:0] MUX_MODE — MUX Mode Select Field.
    5=ALT5 (Select mux mode: ALT5 mux port: GPIO10_IO13 of instance: gpio10)
0x694 SW_MUX_CTL_PAD_GPIO_SPI_B1_00 reset 0x5 — SW_MUX_CTL_PAD_GPIO_SPI_B1_00 SW MUX Control Register
  [4] SION — Software Input On Field.
    0=DISABLED (Input Path is determined by functionality); 1=ENABLED (Force input path of pad GPIO_SPI_B1_00)
  [2:0] MUX_MODE — MUX Mode Select Field.
    0=ALT0 (Select mux mode: ALT0 mux port: FLEXSPI2_A_DQS of instance: flexspi2); 5=ALT5 (Select mux mode: ALT5 mux port: GPIO10_IO14 of instance: gpio10)
0x698 SW_MUX_CTL_PAD_GPIO_SPI_B1_01 reset 0x5 — SW_MUX_CTL_PAD_GPIO_SPI_B1_01 SW MUX Control Register
  [4] SION — Software Input On Field.
    0=DISABLED (Input Path is determined by functionality); 1=ENABLED (Force input path of pad GPIO_SPI_B1_01)
  [2:0] MUX_MODE — MUX Mode Select Field.
    0=ALT0 (Select mux mode: ALT0 mux port: FLEXSPI2_A_DATA03 of instance: flexspi2); 5=ALT5 (Select mux mode: ALT5 mux port: GPIO10_IO15 of instance: gpio10)
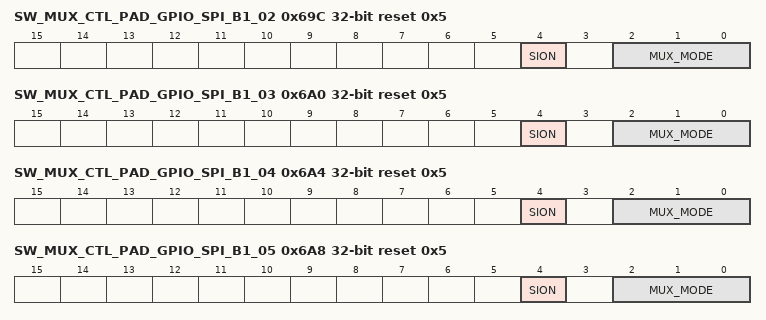
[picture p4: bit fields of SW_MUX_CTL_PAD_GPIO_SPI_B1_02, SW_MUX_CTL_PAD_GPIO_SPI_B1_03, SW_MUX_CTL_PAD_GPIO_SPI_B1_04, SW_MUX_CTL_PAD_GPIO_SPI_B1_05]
0x69C SW_MUX_CTL_PAD_GPIO_SPI_B1_02 reset 0x5 — SW_MUX_CTL_PAD_GPIO_SPI_B1_02 SW MUX Control Register
  [4] SION — Software Input On Field.
    0=DISABLED (Input Path is determined by functionality); 1=ENABLED (Force input path of pad GPIO_SPI_B1_02)
  [2:0] MUX_MODE — MUX Mode Select Field.
    0=ALT0 (Select mux mode: ALT0 mux port: FLEXSPI2_A_DATA02 of instance: flexspi2); 5=ALT5 (Select mux mode: ALT5 mux port: GPIO10_IO16 of instance: gpio10)
0x6A0 SW_MUX_CTL_PAD_GPIO_SPI_B1_03 reset 0x5 — SW_MUX_CTL_PAD_GPIO_SPI_B1_03 SW MUX Control Register
  [4] SION — Software Input On Field.
    0=DISABLED (Input Path is determined by functionality); 1=ENABLED (Force input path of pad GPIO_SPI_B1_03)
  [2:0] MUX_MODE — MUX Mode Select Field.
    0=ALT0 (Select mux mode: ALT0 mux port: FLEXSPI2_A_DATA01 of instance: flexspi2); 5=ALT5 (Select mux mode: ALT5 mux port: GPIO10_IO17 of instance: gpio10)
0x6A4 SW_MUX_CTL_PAD_GPIO_SPI_B1_04 reset 0x5 — SW_MUX_CTL_PAD_GPIO_SPI_B1_04 SW MUX Control Register
  [4] SION — Software Input On Field.
    0=DISABLED (Input Path is determined by functionality); 1=ENABLED (Force input path of pad GPIO_SPI_B1_04)
  [2:0] MUX_MODE — MUX Mode Select Field.
    0=ALT0 (Select mux mode: ALT0 mux port: FLEXSPI2_A_DATA00 of instance: flexspi2); 5=ALT5 (Select mux mode: ALT5 mux port: GPIO10_IO18 of instance: gpio10)
0x6A8 SW_MUX_CTL_PAD_GPIO_SPI_B1_05 reset 0x5 — SW_MUX_CTL_PAD_GPIO_SPI_B1_05 SW MUX Control Register
  [4] SION — Software Input On Field.
    0=DISABLED (Input Path is determined by functionality); 1=ENABLED (Force input path of pad GPIO_SPI_B1_05)
  [2:0] MUX_MODE — MUX Mode Select Field.
    0=ALT0 (Select mux mode: ALT0 mux port: FLEXSPI2_A_SCLK of instance: flexspi2); 5=ALT5 (Select mux mode: ALT5 mux port: GPIO10_IO19 of instance: gpio10)
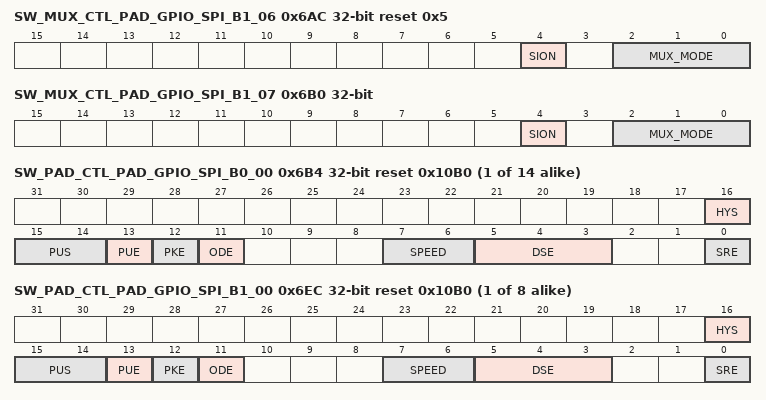
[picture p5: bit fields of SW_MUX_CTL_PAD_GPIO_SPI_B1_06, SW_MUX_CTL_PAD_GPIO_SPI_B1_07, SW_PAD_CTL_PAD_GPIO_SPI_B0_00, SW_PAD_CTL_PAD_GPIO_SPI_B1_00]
0x6AC SW_MUX_CTL_PAD_GPIO_SPI_B1_06 reset 0x5 — SW_MUX_CTL_PAD_GPIO_SPI_B1_06 SW MUX Control Register
  [4] SION — Software Input On Field.
    0=DISABLED (Input Path is determined by functionality); 1=ENABLED (Force input path of pad GPIO_SPI_B1_06)
  [2:0] MUX_MODE — MUX Mode Select Field.
    0=ALT0 (Select mux mode: ALT0 mux port: FLEXSPI2_A_SS0_B of instance: flexspi2); 5=ALT5 (Select mux mode: ALT5 mux port: GPIO10_IO20 of instance: gpio10)
0x6B0 SW_MUX_CTL_PAD_GPIO_SPI_B1_07 — SW_MUX_CTL_PAD_GPIO_SPI_B1_07 SW MUX Control Register
  [4] SION — Software Input On Field.
    0=DISABLED (Input Path is determined by functionality); 1=ENABLED (Force input path of pad GPIO_SPI_B1_07)
  [2:0] MUX_MODE — MUX Mode Select Field.
    5=ALT5 (Select mux mode: ALT5 mux port: GPIO10_IO21 of instance: gpio10)
{0x6B4+4i} SW_PAD_CTL_PAD_GPIO_SPI_B0_{i:02} reset 0x10B0 (i=0..13) — SW_PAD_CTL_PAD_GPIO_SPI_B0_{i:02} SW PAD Control Register
  [16] HYS — Hyst. Enable Field
    0=HYS_0_Hysteresis_Disabled (Hysteresis Disabled); 1=HYS_1_Hysteresis_Enabled (Hysteresis Enabled)
  [15:14] PUS — Pull Up / Down Config. Field
    0=PUS_0_100K_Ohm_Pull_Down (100K Ohm Pull Down); 1=PUS_1_47K_Ohm_Pull_Up (47K Ohm Pull Up); 2=PUS_2_100K_Ohm_Pull_Up (100K Ohm Pull Up); 3=PUS_3_22K_Ohm_Pull_Up (22K Ohm Pull Up)
  [13] PUE — Pull / Keep Select Field
    0=PUE_0_Keeper (Keeper); 1=PUE_1_Pull (Pull)
  [12] PKE — Pull / Keep Enable Field
    0=PKE_0_Pull_Keeper_Disabled (Pull/Keeper Disabled); 1=PKE_1_Pull_Keeper_Enabled (Pull/Keeper Enabled)
  [11] ODE — Open Drain Enable Field
    0=ODE_0_Open_Drain_Disabled (Open Drain Disabled); 1=ODE_1_Open_Drain_Enabled (Open Drain Enabled)
  [7:6] SPEED
    0=SPEED_0_low_50MHz (low(50MHz)); 1=SPEED_1_medium_100MHz (medium(100MHz)); 2=SPEED_2_fast_150MHz (fast(150MHz)); 3=SPEED_3_max_200MHz (max(200MHz))
  [5:3] DSE — Drive Strength Field
    0=DSE_0_output_driver_disabled_ (output driver disabled;); 1=DSE_1_R0_150_Ohm___3_3V__260_Ohm_1_8V_ (R0(150 Ohm @ 3.3V, 260 Ohm@1.8V)); {v}=DSE_{v}_R0_{v} (R0/{v}) (v=2..7)
  [0] SRE — Slew Rate Field
    0=SRE_0_Slow_Slew_Rate (Slow Slew Rate); 1=SRE_1_Fast_Slew_Rate (Fast Slew Rate)
{0x6EC+4i} SW_PAD_CTL_PAD_GPIO_SPI_B1_{i:02} reset 0x10B0 (i=0..7) — SW_PAD_CTL_PAD_GPIO_SPI_B1_{i:02} SW PAD Control Register
  fields as SW_PAD_CTL_PAD_GPIO_SPI_B0_00
0x70C ENET2_IPG_CLK_RMII_SELECT_INPUT — ENET2_IPG_CLK_RMII_SELECT_INPUT DAISY Register
  [1:0] DAISY — Selecting Pads Involved in Daisy Chain.
    0=GPIO_EMC_33_ALT9 (Selecting Pad: GPIO_EMC_33 for Mode: ALT9); 1=GPIO_SD_B0_01_ALT9 (Selecting Pad: GPIO_SD_B0_01 for Mode: ALT9); 2=GPIO_B0_15_ALT9 (Selecting Pad: GPIO_B0_15 for Mode: ALT9)
0x710 ENET2_IPP_IND_MAC0_MDIO_SELECT_INPUT — ENET2_IPP_IND_MAC0_MDIO_SELECT_INPUT DAISY Register
  [0] DAISY — Selecting Pads Involved in Daisy Chain.
    0=GPIO_EMC_39_ALT8 (Selecting Pad: GPIO_EMC_39 for Mode: ALT8); 1=GPIO_B0_01_ALT8 (Selecting Pad: GPIO_B0_01 for Mode: ALT8)
0x714 ENET2_IPP_IND_MAC0_RXDATA_SELECT_INPUT_0 — ENET2_IPP_IND_MAC0_RXDATA_SELECT_INPUT_0 DAISY Register
  [1:0] DAISY — Selecting Pads Involved in Daisy Chain.
    0=GPIO_EMC_35_ALT8 (Selecting Pad: GPIO_EMC_35 for Mode: ALT8); 1=GPIO_SD_B0_03_ALT8 (Selecting Pad: GPIO_SD_B0_03 for Mode: ALT8); 2=GPIO_B1_01_ALT8 (Selecting Pad: GPIO_B1_01 for Mode: ALT8)
0x718 ENET2_IPP_IND_MAC0_RXDATA_SELECT_INPUT_1 — ENET2_IPP_IND_MAC0_RXDATA_SELECT_INPUT_1 DAISY Register
  [1:0] DAISY — Selecting Pads Involved in Daisy Chain.
    0=GPIO_EMC_36_ALT8 (Selecting Pad: GPIO_EMC_36 for Mode: ALT8); 1=GPIO_SD_B0_04_ALT8 (Selecting Pad: GPIO_SD_B0_04 for Mode: ALT8); 2=GPIO_B1_02_ALT8 (Selecting Pad: GPIO_B1_02 for Mode: ALT8)
0x71C ENET2_IPP_IND_MAC0_RXEN_SELECT_INPUT — ENET2_IPP_IND_MAC0_RXEN_SELECT_INPUT DAISY Register
  [1:0] DAISY — Selecting Pads Involved in Daisy Chain.
    0=GPIO_EMC_37_ALT8 (Selecting Pad: GPIO_EMC_37 for Mode: ALT8); 1=GPIO_SD_B0_05_ALT8 (Selecting Pad: GPIO_SD_B0_05 for Mode: ALT8); 2=GPIO_B1_03_ALT8 (Selecting Pad: GPIO_B1_03 for Mode: ALT8)
0x720 ENET2_IPP_IND_MAC0_RXERR_SELECT_INPUT — ENET2_IPP_IND_MAC0_RXERR_SELECT_INPUT DAISY Register
  [1:0] DAISY — Selecting Pads Involved in Daisy Chain.
    0=GPIO_EMC_34_ALT8 (Selecting Pad: GPIO_EMC_34 for Mode: ALT8); 1=GPIO_SD_B0_02_ALT8 (Selecting Pad: GPIO_SD_B0_02 for Mode: ALT8); 2=GPIO_B1_00_ALT8 (Selecting Pad: GPIO_B1_00 for Mode: ALT8)
0x724 ENET2_IPP_IND_MAC0_TIMER_SELECT_INPUT_0 — ENET2_IPP_IND_MAC0_TIMER_SELECT_INPUT_0 DAISY Register
  [0] DAISY — Selecting Pads Involved in Daisy Chain.
    0=GPIO_AD_B1_01_ALT8 (Selecting Pad: GPIO_AD_B1_01 for Mode: ALT8); 1=GPIO_B0_03_ALT8 (Selecting Pad: GPIO_B0_03 for Mode: ALT8)
0x728 ENET2_IPP_IND_MAC0_TXCLK_SELECT_INPUT — ENET2_IPP_IND_MAC0_TXCLK_SELECT_INPUT DAISY Register
  [1:0] DAISY — Selecting Pads Involved in Daisy Chain.
    0=GPIO_EMC_33_ALT8 (Selecting Pad: GPIO_EMC_33 for Mode: ALT8); 1=GPIO_SD_B0_01_ALT8 (Selecting Pad: GPIO_SD_B0_01 for Mode: ALT8); 2=GPIO_B0_15_ALT8 (Selecting Pad: GPIO_B0_15 for Mode: ALT8)
0x72C FLEXSPI2_IPP_IND_DQS_FA_SELECT_INPUT — FLEXSPI2_IPP_IND_DQS_FA_SELECT_INPUT DAISY Register
  [1:0] DAISY — Selecting Pads Involved in Daisy Chain.
    0=GPIO_SPI_B1_00_ALT0 (Selecting Pad: GPIO_SPI_B1_00 for Mode: ALT0); 1=GPIO_EMC_23_ALT8 (Selecting Pad: GPIO_EMC_23 for Mode: ALT8); 2=GPIO_SPI_B0_09_ALT0 (Selecting Pad: GPIO_SPI_B0_09 for Mode: ALT0)
0x730 FLEXSPI2_IPP_IND_IO_FA_BIT0_SELECT_INPUT — FLEXSPI2_IPP_IND_IO_FA_BIT0_SELECT_INPUT DAISY Register
  [1:0] DAISY — Selecting Pads Involved in Daisy Chain.
    0=GPIO_SPI_B1_04_ALT0 (Selecting Pad: GPIO_SPI_B1_04 for Mode: ALT0); 1=GPIO_EMC_26_ALT8 (Selecting Pad: GPIO_EMC_26 for Mode: ALT8); 2=GPIO_SPI_B0_02_ALT0 (Selecting Pad: GPIO_SPI_B0_02 for Mode: ALT0)
0x734 FLEXSPI2_IPP_IND_IO_FA_BIT1_SELECT_INPUT — FLEXSPI2_IPP_IND_IO_FA_BIT1_SELECT_INPUT DAISY Register
  [1:0] DAISY — Selecting Pads Involved in Daisy Chain.
    0=GPIO_SPI_B1_03_ALT0 (Selecting Pad: GPIO_SPI_B1_03 for Mode: ALT0); 1=GPIO_EMC_27_ALT8 (Selecting Pad: GPIO_EMC_27 for Mode: ALT8); 2=GPIO_SPI_B0_12_ALT0 (Selecting Pad: GPIO_SPI_B0_12 for Mode: ALT0)
0x738 FLEXSPI2_IPP_IND_IO_FA_BIT2_SELECT_INPUT — FLEXSPI2_IPP_IND_IO_FA_BIT2_SELECT_INPUT DAISY Register
  [1:0] DAISY — Selecting Pads Involved in Daisy Chain.
    0=GPIO_SPI_B1_02_ALT0 (Selecting Pad: GPIO_SPI_B1_02 for Mode: ALT0); 1=GPIO_EMC_28_ALT8 (Selecting Pad: GPIO_EMC_28 for Mode: ALT8); 2=GPIO_SPI_B0_06_ALT0 (Selecting Pad: GPIO_SPI_B0_06 for Mode: ALT0)
0x73C FLEXSPI2_IPP_IND_IO_FA_BIT3_SELECT_INPUT — FLEXSPI2_IPP_IND_IO_FA_BIT3_SELECT_INPUT DAISY Register
  [1:0] DAISY — Selecting Pads Involved in Daisy Chain.
    0=GPIO_SPI_B1_01_ALT0 (Selecting Pad: GPIO_SPI_B1_01 for Mode: ALT0); 1=GPIO_EMC_29_ALT8 (Selecting Pad: GPIO_EMC_29 for Mode: ALT8); 2=GPIO_SPI_B0_10_ALT0 (Selecting Pad: GPIO_SPI_B0_10 for Mode: ALT0)
0x740 FLEXSPI2_IPP_IND_IO_FB_BIT0_SELECT_INPUT — FLEXSPI2_IPP_IND_IO_FB_BIT0_SELECT_INPUT DAISY Register
  [0] DAISY — Selecting Pads Involved in Daisy Chain.
    0=GPIO_EMC_13_ALT8 (Selecting Pad: GPIO_EMC_13 for Mode: ALT8); 1=GPIO_SPI_B0_11_ALT0 (Selecting Pad: GPIO_SPI_B0_11 for Mode: ALT0)
0x744 FLEXSPI2_IPP_IND_IO_FB_BIT1_SELECT_INPUT — FLEXSPI2_IPP_IND_IO_FB_BIT1_SELECT_INPUT DAISY Register
  [0] DAISY — Selecting Pads Involved in Daisy Chain.
    0=GPIO_EMC_14_ALT8 (Selecting Pad: GPIO_EMC_14 for Mode: ALT8); 1=GPIO_SPI_B0_07_ALT0 (Selecting Pad: GPIO_SPI_B0_07 for Mode: ALT0)
0x748 FLEXSPI2_IPP_IND_IO_FB_BIT2_SELECT_INPUT — FLEXSPI2_IPP_IND_IO_FB_BIT2_SELECT_INPUT DAISY Register
  [0] DAISY — Selecting Pads Involved in Daisy Chain.
    0=GPIO_EMC_15_ALT8 (Selecting Pad: GPIO_EMC_15 for Mode: ALT8); 1=GPIO_SPI_B0_03_ALT0 (Selecting Pad: GPIO_SPI_B0_03 for Mode: ALT0)
0x74C FLEXSPI2_IPP_IND_IO_FB_BIT3_SELECT_INPUT — FLEXSPI2_IPP_IND_IO_FB_BIT3_SELECT_INPUT DAISY Register
  [0] DAISY — Selecting Pads Involved in Daisy Chain.
    0=GPIO_EMC_16_ALT8 (Selecting Pad: GPIO_EMC_16 for Mode: ALT8); 1=GPIO_SPI_B0_04_ALT0 (Selecting Pad: GPIO_SPI_B0_04 for Mode: ALT0)
0x750 FLEXSPI2_IPP_IND_SCK_FA_SELECT_INPUT — FLEXSPI2_IPP_IND_SCK_FA_SELECT_INPUT DAISY Register
  [1:0] DAISY — Selecting Pads Involved in Daisy Chain.
    0=GPIO_SPI_B1_05_ALT0 (Selecting Pad: GPIO_SPI_B1_05 for Mode: ALT0); 1=GPIO_EMC_25_ALT8 (Selecting Pad: GPIO_EMC_25 for Mode: ALT8); 2=GPIO_SPI_B0_08_ALT0 (Selecting Pad: GPIO_SPI_B0_08 for Mode: ALT0)
0x754 FLEXSPI2_IPP_IND_SCK_FB_SELECT_INPUT — FLEXSPI2_IPP_IND_SCK_FB_SELECT_INPUT DAISY Register
  [0] DAISY — Selecting Pads Involved in Daisy Chain.
    0=GPIO_EMC_12_ALT8 (Selecting Pad: GPIO_EMC_12 for Mode: ALT8); 1=GPIO_SPI_B0_01_ALT0 (Selecting Pad: GPIO_SPI_B0_01 for Mode: ALT0)
0x758 GPT1_IPP_IND_CAPIN1_SELECT_INPUT — GPT1_IPP_IND_CAPIN1_SELECT_INPUT DAISY Register
  [0] DAISY — Selecting Pads Involved in Daisy Chain.
    0=GPIO_EMC_24_ALT4 (Selecting Pad: GPIO_EMC_24 for Mode: ALT4); 1=GPIO_B1_05_ALT8 (Selecting Pad: GPIO_B1_05 for Mode: ALT8)
0x75C GPT1_IPP_IND_CAPIN2_SELECT_INPUT — GPT1_IPP_IND_CAPIN2_SELECT_INPUT DAISY Register
  [0] DAISY — Selecting Pads Involved in Daisy Chain.
    0=GPIO_EMC_23_ALT4 (Selecting Pad: GPIO_EMC_23 for Mode: ALT4); 1=GPIO_B1_06_ALT8 (Selecting Pad: GPIO_B1_06 for Mode: ALT8)
0x760 GPT1_IPP_IND_CLKIN_SELECT_INPUT — GPT1_IPP_IND_CLKIN_SELECT_INPUT DAISY Register
  [0] DAISY — Selecting Pads Involved in Daisy Chain.
    0=GPIO_AD_B0_13_ALT1 (Selecting Pad: GPIO_AD_B0_13 for Mode: ALT1); 1=GPIO_B1_04_ALT8 (Selecting Pad: GPIO_B1_04 for Mode: ALT8)
0x764 GPT2_IPP_IND_CAPIN1_SELECT_INPUT — GPT2_IPP_IND_CAPIN1_SELECT_INPUT DAISY Register
  [0] DAISY — Selecting Pads Involved in Daisy Chain.
    0=GPIO_EMC_41_ALT1 (Selecting Pad: GPIO_EMC_41 for Mode: ALT1); 1=GPIO_AD_B1_03_ALT8 (Selecting Pad: GPIO_AD_B1_03 for Mode: ALT8)
0x768 GPT2_IPP_IND_CAPIN2_SELECT_INPUT — GPT2_IPP_IND_CAPIN2_SELECT_INPUT DAISY Register
  [0] DAISY — Selecting Pads Involved in Daisy Chain.
    0=GPIO_EMC_40_ALT1 (Selecting Pad: GPIO_EMC_40 for Mode: ALT1); 1=GPIO_AD_B1_04_ALT8 (Selecting Pad: GPIO_AD_B1_04 for Mode: ALT8)
0x76C GPT2_IPP_IND_CLKIN_SELECT_INPUT — GPT2_IPP_IND_CLKIN_SELECT_INPUT DAISY Register
  [0] DAISY — Selecting Pads Involved in Daisy Chain.
    0=GPIO_AD_B0_09_ALT7 (Selecting Pad: GPIO_AD_B0_09 for Mode: ALT7); 1=GPIO_AD_B1_02_ALT8 (Selecting Pad: GPIO_AD_B1_02 for Mode: ALT8)
0x770 SAI3_IPG_CLK_SAI_MCLK_SELECT_INPUT_2 — SAI3_IPG_CLK_SAI_MCLK_SELECT_INPUT_2 DAISY Register
  [0] DAISY — Selecting Pads Involved in Daisy Chain.
    0=GPIO_EMC_37_ALT3 (Selecting Pad: GPIO_EMC_37 for Mode: ALT3); 1=GPIO_SD_B1_04_ALT8 (Selecting Pad: GPIO_SD_B1_04 for Mode: ALT8)
0x774 SAI3_IPP_IND_SAI_RXBCLK_SELECT_INPUT — SAI3_IPP_IND_SAI_RXBCLK_SELECT_INPUT DAISY Register
  [0] DAISY — Selecting Pads Involved in Daisy Chain.
    0=GPIO_EMC_35_ALT3 (Selecting Pad: GPIO_EMC_35 for Mode: ALT3); 1=GPIO_SD_B1_06_ALT8 (Selecting Pad: GPIO_SD_B1_06 for Mode: ALT8)
0x778 SAI3_IPP_IND_SAI_RXDATA_SELECT_INPUT_0 — SAI3_IPP_IND_SAI_RXDATA_SELECT_INPUT_0 DAISY Register
  [0] DAISY — Selecting Pads Involved in Daisy Chain.
    0=GPIO_EMC_33_ALT3 (Selecting Pad: GPIO_EMC_33 for Mode: ALT3); 1=GPIO_SD_B1_00_ALT8 (Selecting Pad: GPIO_SD_B1_00 for Mode: ALT8)
0x77C SAI3_IPP_IND_SAI_RXSYNC_SELECT_INPUT — SAI3_IPP_IND_SAI_RXSYNC_SELECT_INPUT DAISY Register
  [0] DAISY — Selecting Pads Involved in Daisy Chain.
    0=GPIO_EMC_34_ALT3 (Selecting Pad: GPIO_EMC_34 for Mode: ALT3); 1=GPIO_SD_B1_05_ALT8 (Selecting Pad: GPIO_SD_B1_05 for Mode: ALT8)
0x780 SAI3_IPP_IND_SAI_TXBCLK_SELECT_INPUT — SAI3_IPP_IND_SAI_TXBCLK_SELECT_INPUT DAISY Register
  [0] DAISY — Selecting Pads Involved in Daisy Chain.
    0=GPIO_EMC_38_ALT3 (Selecting Pad: GPIO_EMC_38 for Mode: ALT3); 1=GPIO_SD_B1_03_ALT8 (Selecting Pad: GPIO_SD_B1_03 for Mode: ALT8)
0x784 SAI3_IPP_IND_SAI_TXSYNC_SELECT_INPUT — SAI3_IPP_IND_SAI_TXSYNC_SELECT_INPUT DAISY Register
  [0] DAISY — Selecting Pads Involved in Daisy Chain.
    0=GPIO_EMC_39_ALT3 (Selecting Pad: GPIO_EMC_39 for Mode: ALT3); 1=GPIO_SD_B1_02_ALT8 (Selecting Pad: GPIO_SD_B1_02 for Mode: ALT8)
0x788 SEMC_I_IPP_IND_DQS4_SELECT_INPUT — SEMC_I_IPP_IND_DQS4_SELECT_INPUT DAISY Register
  [1:0] DAISY — Selecting Pads Involved in Daisy Chain.
    0=GPIO_SD_B0_00_ALT9 (Selecting Pad: GPIO_SD_B0_00 for Mode: ALT9); 1=GPIO_EMC_39_ALT9 (Selecting Pad: GPIO_EMC_39 for Mode: ALT9); 2=GPIO_AD_B0_09_ALT9 (Selecting Pad: GPIO_AD_B0_09 for Mode: ALT9); 3=GPIO_B1_13_ALT8 (Selecting Pad: GPIO_B1_13 for Mode: ALT8)
0x78C CANFD_IPP_IND_CANRX_SELECT_INPUT — CANFD_IPP_IND_CANRX_SELECT_INPUT DAISY Register
  [1:0] DAISY — Selecting Pads Involved in Daisy Chain.
    0=GPIO_EMC_37_ALT9 (Selecting Pad: GPIO_EMC_37 for Mode: ALT9); 1=GPIO_AD_B0_15_ALT8 (Selecting Pad: GPIO_AD_B0_15 for Mode: ALT8); 2=GPIO_AD_B0_11_ALT8 (Selecting Pad: GPIO_AD_B0_11 for Mode: ALT8)
